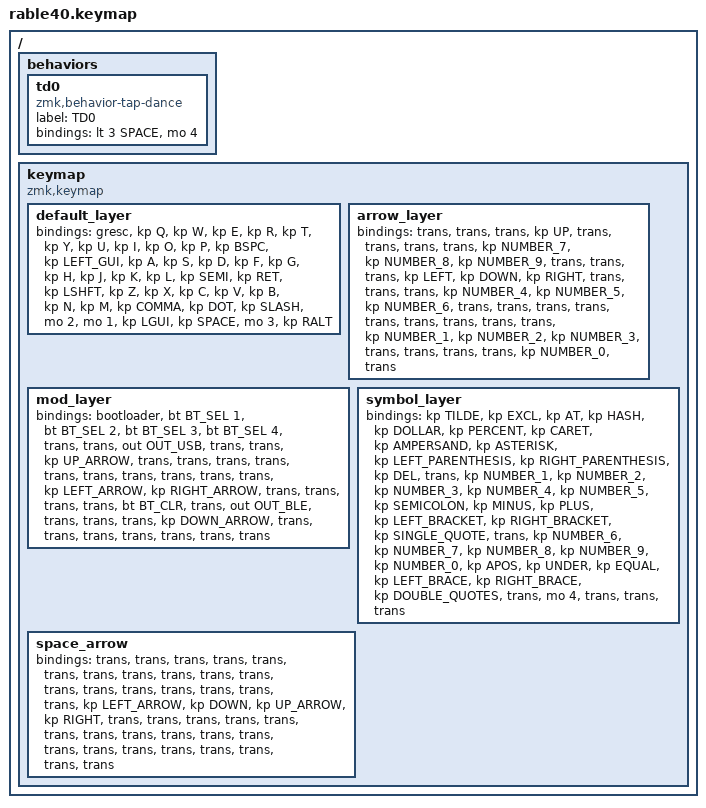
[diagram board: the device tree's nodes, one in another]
/*
 * Copyright (c) 2021 Nick Winans
 *
 * SPDX-License-Identifier: MIT
 */

#include <behaviors.dtsi>
#include <dt-bindings/zmk/bt.h>
#include <dt-bindings/zmk/keys.h>
#include <dt-bindings/zmk/outputs.h>

/ {
    behaviors {
        td0: td0 {
            compatible = "zmk,behavior-tap-dance";
            label = "TD0";
            #binding-cells = <0>;
            bindings = <&lt 3 SPACE>, <&mo 4>;
        };
    };

    keymap {
        compatible = "zmk,keymap";

        default_layer {
            bindings = <
&gresc  &kp Q  &kp W  &kp E  &kp R  &kp T  &kp Y  &kp U  &kp I  &kp O  &kp P  &kp BSPC  &kp LEFT_GUI  &kp A  &kp S  &kp D  &kp F  &kp G  &kp H  &kp J  &kp K  &kp L  &kp SEMI  &kp RET  &kp LSHFT  &kp Z  &kp X  &kp C  &kp V  &kp B  &kp N  &kp M  &kp COMMA  &kp DOT  &kp SLASH  &mo 2  &mo 1  &kp LGUI  &kp SPACE  &mo 3  &kp RALT
            >;
        };

        arrow_layer {
            bindings = <
&trans  &trans  &trans  &kp UP  &trans  &trans  &trans  &trans  &kp NUMBER_7  &kp NUMBER_8  &kp NUMBER_9  &trans  &trans  &trans  &kp LEFT  &kp DOWN  &kp RIGHT  &trans  &trans  &trans  &kp NUMBER_4  &kp NUMBER_5  &kp NUMBER_6  &trans  &trans  &trans  &trans  &trans  &trans  &trans  &trans  &trans  &kp NUMBER_1  &kp NUMBER_2  &kp NUMBER_3  &trans  &trans  &trans  &trans  &kp NUMBER_0  &trans
            >;
        };

        mod_layer {
            bindings = <
&bootloader  &bt BT_SEL 1  &bt BT_SEL 2  &bt BT_SEL 3  &bt BT_SEL 4  &trans  &trans  &out OUT_USB  &trans  &trans  &kp UP_ARROW  &trans  &trans  &trans  &trans  &trans  &trans  &trans  &trans  &trans  &trans  &kp LEFT_ARROW  &kp RIGHT_ARROW  &trans  &trans  &trans  &trans  &bt BT_CLR  &trans  &out OUT_BLE  &trans  &trans  &trans  &kp DOWN_ARROW  &trans  &trans  &trans  &trans  &trans  &trans  &trans
            >;
        };

        symbol_layer {
            bindings = <
&kp TILDE  &kp EXCL  &kp AT  &kp HASH  &kp DOLLAR  &kp PERCENT  &kp CARET  &kp AMPERSAND  &kp ASTERISK  &kp LEFT_PARENTHESIS  &kp RIGHT_PARENTHESIS  &kp DEL  &trans  &kp NUMBER_1  &kp NUMBER_2  &kp NUMBER_3  &kp NUMBER_4  &kp NUMBER_5  &kp SEMICOLON  &kp MINUS  &kp PLUS  &kp LEFT_BRACKET  &kp RIGHT_BRACKET  &kp SINGLE_QUOTE  &trans  &kp NUMBER_6  &kp NUMBER_7  &kp NUMBER_8  &kp NUMBER_9  &kp NUMBER_0  &kp APOS  &kp UNDER  &kp EQUAL  &kp LEFT_BRACE  &kp RIGHT_BRACE  &kp DOUBLE_QUOTES  &trans  &mo 4  &trans  &trans  &trans
            >;
        };

        space_arrow {
            bindings = <
&trans  &trans  &trans  &trans  &trans  &trans  &trans  &trans  &trans  &trans  &trans  &trans  &trans  &trans  &trans  &trans  &trans  &trans  &kp LEFT_ARROW  &kp DOWN  &kp UP_ARROW  &kp RIGHT  &trans  &trans  &trans  &trans  &trans  &trans  &trans  &trans  &trans  &trans  &trans  &trans  &trans  &trans  &trans  &trans  &trans  &trans  &trans
            >;
        };
    };
};
